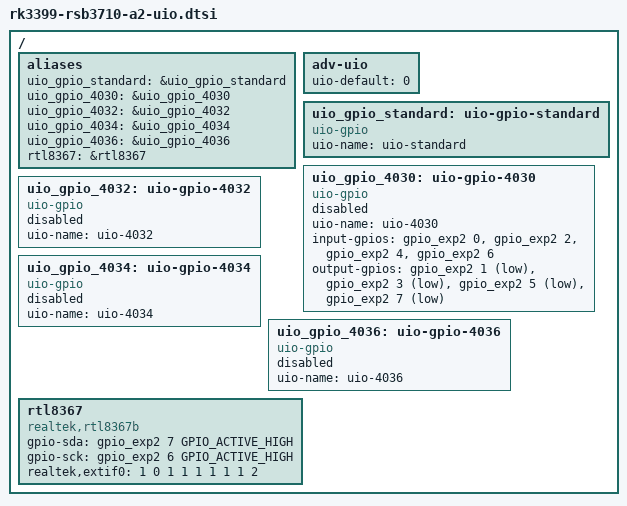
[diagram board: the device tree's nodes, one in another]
/*
 * Copyright (c) 2019 Fuzhou Rockchip Electronics Co., Ltd
 *
 * This file is dual-licensed: you can use it either under the terms
 * of the GPL or the X11 license, at your option. Note that this dual
 * licensing only applies to this file, and not this project as a
 * whole.
 *
 *  a) This file is free software; you can redistribute it and/or
 *     modify it under the terms of the GNU General Public License as
 *     published by the Free Software Foundation; either version 2 of the
 *     License, or (at your option) any later version.
 *
 *     This file is distributed in the hope that it will be useful,
 *     but WITHOUT ANY WARRANTY; without even the implied warranty of
 *     MERCHANTABILITY or FITNESS FOR A PARTICULAR PURPOSE.  See the
 *     GNU General Public License for more details.
 *
 * Or, alternatively,
 *
 *  b) Permission is hereby granted, free of charge, to any person
 *     obtaining a copy of this software and associated documentation
 *     files (the "Software"), to deal in the Software without
 *     restriction, including without limitation the rights to use,
 *     copy, modify, merge, publish, distribute, sublicense, and/or
 *     sell copies of the Software, and to permit persons to whom the
 *     Software is furnished to do so, subject to the following
 *     conditions:
 *
 *     The above copyright notice and this permission notice shall be
 *     included in all copies or substantial portions of the Software.
 *
 *     THE SOFTWARE IS PROVIDED "AS IS", WITHOUT WARRANTY OF ANY KIND,
 *     EXPRESS OR IMPLIED, INCLUDING BUT NOT LIMITED TO THE WARRANTIES
 *     OF MERCHANTABILITY, FITNESS FOR A PARTICULAR PURPOSE AND
 *     NONINFRINGEMENT. IN NO EVENT SHALL THE AUTHORS OR COPYRIGHT
 *     HOLDERS BE LIABLE FOR ANY CLAIM, DAMAGES OR OTHER LIABILITY,
 *     WHETHER IN AN ACTION OF CONTRACT, TORT OR OTHERWISE, ARISING
 *     FROM, OUT OF OR IN CONNECTION WITH THE SOFTWARE OR THE USE OR
 *     OTHER DEALINGS IN THE SOFTWARE.
 */

/ {
	aliases {
		uio_gpio_standard = &uio_gpio_standard;
		uio_gpio_4030 = &uio_gpio_4030;
		uio_gpio_4032 = &uio_gpio_4032;
		uio_gpio_4034 = &uio_gpio_4034;
		uio_gpio_4036 = &uio_gpio_4036;

		rtl8367 = &rtl8367;
	};

	adv-uio {
		// 0      standard
		// 4030   uio-4030
		// 4032   uio-4032
		// 4034   uio-4034
		// 4036   uio-4036
		uio-default = <0>;
	};

	uio_gpio_standard: uio-gpio-standard {
		compatible = "uio-gpio";
		uio-name = "uio-standard";

		status = "okay";
	};

	uio_gpio_4030: uio-gpio-4030 {
		compatible = "uio-gpio";
		uio-name = "uio-4030";

		input-gpios = <&gpio_exp2 0 GPIO_ACTIVE_HIGH
			       &gpio_exp2 2 GPIO_ACTIVE_HIGH
			       &gpio_exp2 4 GPIO_ACTIVE_HIGH
			       &gpio_exp2 6 GPIO_ACTIVE_HIGH>;

		output-gpios = <&gpio_exp2 1 GPIO_ACTIVE_LOW
			        &gpio_exp2 3 GPIO_ACTIVE_LOW
			        &gpio_exp2 5 GPIO_ACTIVE_LOW
			        &gpio_exp2 7 GPIO_ACTIVE_LOW>;

		status = "disabled";
	};

	uio_gpio_4032: uio-gpio-4032 {
		compatible = "uio-gpio";
		uio-name = "uio-4032";

		//lan-pwren-gpio = <&gpio_exp1 1 GPIO_ACTIVE_HIGH>;
		//lan-reset-gpio = <&gpio_exp1 3 GPIO_ACTIVE_LOW>;
		//timing-interval = <50>;

		status = "disabled";
	};

	uio_gpio_4034: uio-gpio-4034 {
		compatible = "uio-gpio";
		uio-name = "uio-4034";

		status = "disabled";
	};


	uio_gpio_4036: uio-gpio-4036 {
		compatible = "uio-gpio";
		uio-name = "uio-4036";

		//lan-pwren-gpio = <&gpio_exp2 1 GPIO_ACTIVE_HIGH>;
		//lan-reset-gpio = <&gpio_exp2 3 GPIO_ACTIVE_LOW>;
		//timing-interval = <50>;

		status = "disabled";

	};

 	rtl8367:rtl8367 {
		compatible = "realtek,rtl8367b";
		pinctrl-names = "default";
		gpio-sda = <&gpio_exp2 7 GPIO_ACTIVE_HIGH>;
		gpio-sck = <&gpio_exp2 6 GPIO_ACTIVE_HIGH>;
		realtek,extif0 = <1 0 1 1 1 1 1 1 2>;
		status = "okay";
	};

};






		
